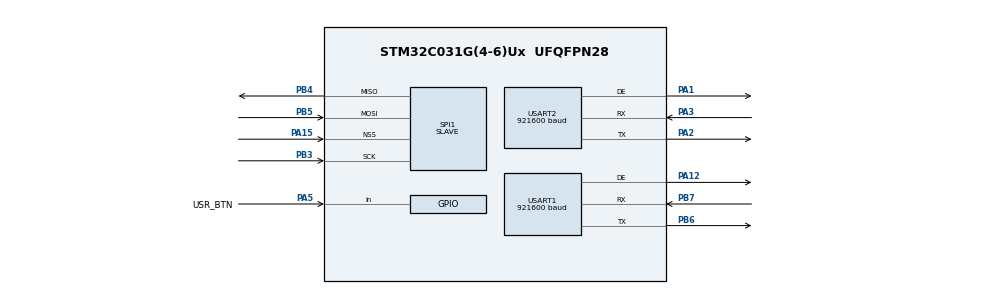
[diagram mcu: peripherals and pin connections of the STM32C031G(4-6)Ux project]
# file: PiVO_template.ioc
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Mcu.Family=STM32C0
Mcu.Name=STM32C031G(4-6)Ux
Mcu.Package=UFQFPN28
NVIC.TIM14_IRQn=true\:2\:0\:true\:false\:true\:true\:true\:true
NVIC.TIM16_IRQn=true\:1\:0\:true\:false\:true\:true\:true\:true
NVIC.USART1_IRQn=true\:1\:0\:true\:false\:true\:true\:true\:true
NVIC.USART2_IRQn=true\:0\:0\:false\:false\:true\:true\:true\:true
PA1.Mode=Hardware Flow Control (RS485)
PA1.Signal=USART2_DE
PA12\ [PA10].Mode=Hardware Flow Control (RS485)
PA12\ [PA10].Signal=USART1_DE
PA13.Mode=Serial_Wire
PA13.Signal=DEBUG_SWDIO
PA14-BOOT0.Mode=Serial_Wire
PA14-BOOT0.Signal=DEBUG_SWCLK
PA15.Mode=NSS_Signal_Hard_Input
PA15.Signal=SPI1_NSS
PA2.Mode=Asynchronous
PA2.Signal=USART2_TX
PA3.Mode=Asynchronous
PA3.Signal=USART2_RX
PA5.GPIO_Label=USR_BTN
PA5.GPIO_PuPd=GPIO_PULLUP
PA5.Signal=GPIO_Input
PB3.Mode=Full_Duplex_Slave
PB3.Signal=SPI1_SCK
PB4.Mode=Full_Duplex_Slave
PB4.Signal=SPI1_MISO
PB5.Mode=Full_Duplex_Slave
PB5.Signal=SPI1_MOSI
PB6.Mode=Asynchronous
PB6.Signal=USART1_TX
PB7.Mode=Asynchronous
PB7.Signal=USART1_RX
ProjectManager.HeapSize=0x200
ProjectManager.StackSize=0x400
ProjectManager.TargetToolchain=STM32CubeIDE
RCC.ADCFreq_Value=48000000
RCC.AHBFreq_Value=48000000
RCC.CortexFreq_Value=48000000
RCC.EXTERNAL_CLOCK_VALUE=12288000
RCC.HCLKFreq_Value=48000000
RCC.HSE_VALUE=8000000
RCC.HSISYSCLKDivider=RCC_HSI_DIV1
RCC.HSI_VALUE=48000000
RCC.LSE_VALUE=32768
RCC.SYSCLKFreq_VALUE=48000000
SPI1.Direction=SPI_DIRECTION_2LINES
SPI1.Mode=SPI_MODE_SLAVE
SPI1.VirtualNSS=VM_NSSHARD
SPI1.VirtualType=VM_SLAVE
TIM14.Period=4799
TIM14.Prescaler=50
TIM16.Period=2000
TIM16.Prescaler=34
USART1.BaudRate=921600
USART1.StopBits=STOPBITS_2
USART1.VirtualMode-Asynchronous=VM_ASYNC
USART1.VirtualMode-Hardware\ Flow\ Control\ (RS485)=VM_ASYNC
USART2.BaudRate=921600
USART2.StopBits=STOPBITS_2
USART2.VirtualMode-Asynchronous=VM_ASYNC
USART2.VirtualMode-Hardware\ Flow\ Control\ (RS485)=VM_ASYNC
VP_TIM14_VS_ClockSourceINT.Mode=Enable_Timer
VP_TIM16_VS_ClockSourceINT.Mode=Enable_Timer
board=custom

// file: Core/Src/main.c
/* USER CODE BEGIN Header */
/**
  ******************************************************************************
  * @file           : main.c
  * @brief          : Main program body
  ******************************************************************************
  * @attention
  *
  * Copyright (c) 2024 STMicroelectronics.
  * All rights reserved.
  *
  * This software is licensed under terms that can be found in the LICENSE file
  * in the root directory of this software component.
  * If no LICENSE file comes with this software, it is provided AS-IS.
  *
  ******************************************************************************
  */
/* USER CODE END Header */
#include "main.h"
#include "spi.h"
#include "tim.h"
#include "usart.h"
#include "gpio.h"

/* USER CODE BEGIN Includes */
#include "mb.h"
#include "port.h"
#include "mbport.h"

#include "housekeep.h"
#include "settings.h"
/* USER CODE END Includes */

/* USER CODE BEGIN PV */
extern USHORT   usRegInputBuf[REG_INPUT_NREGS];
extern USHORT   usRegHoldingBuf[REG_HOLDING_NREGS];
extern USHORT   usRegCoilBuf[REG_COIL_NREGS];
extern USHORT   usRegDiscreteBuf[REG_DISCRETE_NREGS];
/* USER CODE END PV */

void SystemClock_Config(void);

int main(void)
{

  /* MCU Configuration--------------------------------------------------------*/

  /* Reset of all peripherals, Initializes the Flash interface and the Systick. */
  HAL_Init();

  /* Configure the system clock */
  SystemClock_Config();

  /* Initialize all configured peripherals */
  MX_GPIO_Init();
  MX_SPI1_Init();
  MX_TIM14_Init();
  MX_TIM16_Init();
  MX_USART1_UART_Init();
  MX_USART2_UART_Init();
  /* USER CODE BEGIN 2 */

  settings_init();

  MB_startup();
  start_housekeeping();

  /* USER CODE END 2 */

  /* Infinite loop */
  while (1)
  {

    /* USER CODE BEGIN 3 */
	  if(eMBPoll()!=MB_ENOERR)Error_Handler();  /*Modbus poll update in each run*/

  }
  /* USER CODE END 3 */
}

void SystemClock_Config(void)
{
  RCC_OscInitTypeDef RCC_OscInitStruct = {0};
  RCC_ClkInitTypeDef RCC_ClkInitStruct = {0};

  /** Initializes the RCC Oscillators according to the specified parameters
  * in the RCC_OscInitTypeDef structure.
  */
  RCC_OscInitStruct.OscillatorType = RCC_OSCILLATORTYPE_HSI;
  RCC_OscInitStruct.HSIState = RCC_HSI_ON;
  RCC_OscInitStruct.HSIDiv = RCC_HSI_DIV1;
  RCC_OscInitStruct.HSICalibrationValue = RCC_HSICALIBRATION_DEFAULT;
  if (HAL_RCC_OscConfig(&RCC_OscInitStruct) != HAL_OK)
  {
    Error_Handler();
  }

  /** Initializes the CPU, AHB and APB buses clocks
  */
  RCC_ClkInitStruct.ClockType = RCC_CLOCKTYPE_HCLK|RCC_CLOCKTYPE_SYSCLK
                              |RCC_CLOCKTYPE_PCLK1;
  RCC_ClkInitStruct.SYSCLKSource = RCC_SYSCLKSOURCE_HSI;
  RCC_ClkInitStruct.SYSCLKDivider = RCC_SYSCLK_DIV1;
  RCC_ClkInitStruct.AHBCLKDivider = RCC_HCLK_DIV1;
  RCC_ClkInitStruct.APB1CLKDivider = RCC_APB1_DIV1;

  if (HAL_RCC_ClockConfig(&RCC_ClkInitStruct, FLASH_LATENCY_1) != HAL_OK)
  {
    Error_Handler();
  }
}

void Error_Handler(void)
{
  __disable_irq();
  while (1)
  {
  }
}
